# TC37XPD register map
Vendor: Infineon; Series: ATVMC; File version: 100
CPU: other r0p0, little endian, MPU, FPU, vendor SysTick, 4 interrupt priority bits
Registers are 32-bit, read-write, reset 0x0 unless marked. A register's access mark holds for its fields unless they carry their own. Offsets are from the block's base; [hi:lo] are bit positions; lines under a group give offsets from that group; {n}, {i} and the like mark numbered series.

## DOM0 — DOM
Base 0xF8700000
{0x0+0x20*i} SCICTRL[{i}] (i=0..15) group
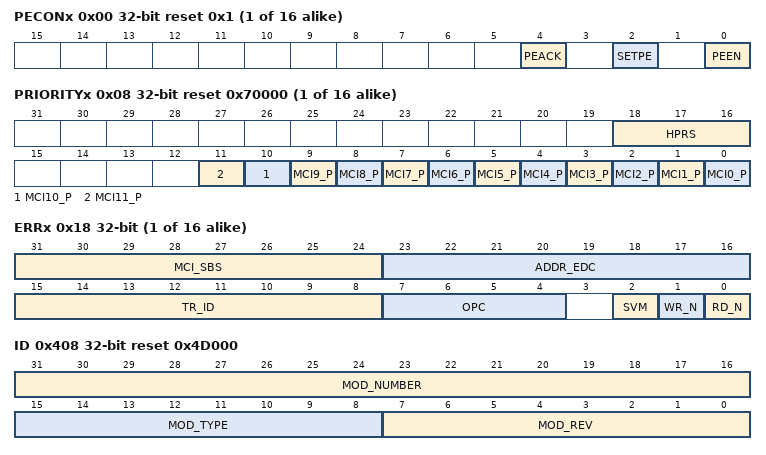
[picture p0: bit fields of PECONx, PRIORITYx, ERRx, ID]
  0x00 PECONx reset 0x1 — Protocol Error Control Register 0 resetvalue={Application Reset:0x1}
    [4] PEACK — Protocol Error Acknowledge PEACK. Writing a one to this bit while it x2019 s set has the following results The error lock of the corresponding ERRADDRx and ERRx are released and the registers will be updated for the next protocol error detected see CROSSREFERENCE . After setting this bit it is automatically cleared by the hardware in the cycle after the write.
    [2] SETPE — Set Protocol Error SETPE. This allows SW to mimic a protocol error and present an indication similar to a hardware detected error. After setting this bit it is automatically cleared by the hardware in the cycle after the write.
    [0] PEEN — Protocol Error Enable PEEN
  0x08 PRIORITYx reset 0x70000 (reset mask 0xFFFFF000) — SCI0 Arbiter Priority Register resetvalue={Application Reset:0x70000}
    [18:16] HPRS — High Priority Round Share HPRS. Number of transactions to give to the high priority round robin before a transaction from low priority round when request saturated . This number may not be less than the number of high priority MCI programmed via. MCIn P.
    [n] MCI{n}_P (n=0..11) — MCI11 Priority MCI11 P
  0x10 ERRADDRx ro — SCI 0 Error Address Capture Register resetvalue={Application Reset:0x0}
    [31:0] ADDR — Transaction Address ADDR. This bitfield contains the address of the erroneous transaction from the address phase
  0x18 ERRx ro — SCI 0 Error Capture Register resetvalue={Application Reset:0x0}
    [31:24] MCI_SBS — MCI Sideband Signals 7 0 MCI SBS. This bit field contains the MCI Sideband Signals 7 0 that are related to the transaction information captured. In the AURIX 8482 TC3xx family the sideband signals are used by the DMA to provide information about the DMA requestor of a DMA transaction for the encoding see CROSSREFERENCE .
    [23:16] ADDR_EDC — Address Phase Error Detection Information ADDR EDC. This field contains the Address Phase Error Detection Information of the erroneous transaction.
    [15:8] TR_ID — Transaction ID TR ID. This field contains the Master 8217 s transaction ID of the erroneous transaction. The Transaction ID is built out of the Master 8217 s 6 bit unique TAG ID TR ID 5 0 and a 2 bit running number TR ID 7 6 .
    [7:4] OPC — Operation Code OPC. This field contains the opcode of the erroneous transaction see CROSSREFERENCE for details.
    [2] SVM — Supervisor Mode Status SVM
    [1] WR_N — Write Status WR
    [0] RD_N — Read Status RD
0x408 ID ro reset 0x4D000 (reset mask 0xFFFFFF00) — Identification Register resetvalue={Application Reset:0x4D000}
  [31:16] MOD_NUMBER — Module Number Value MOD NUMBER. This bit field defines a module identification number. The value for the lt Default Font gt SRI Fabric is 0004H.
  [15:8] MOD_TYPE — Module Type MOD TYPE. The bit field is set to D0H which defines the module as a 32 bit module.
  [7:0] MOD_REV — Module Revision Number MOD REV. This bit field defines the module revision number. The value of a module revision starts with 01H first revision .
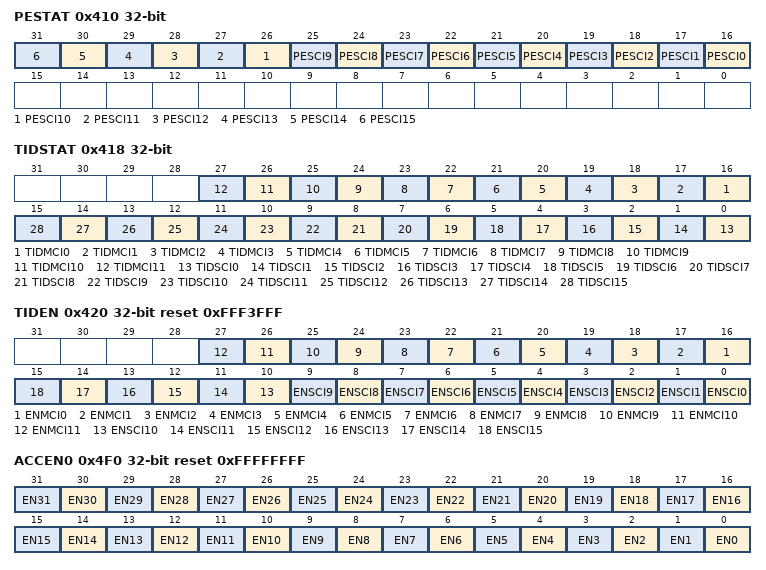
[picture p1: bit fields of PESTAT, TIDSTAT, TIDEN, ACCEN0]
0x410 PESTAT — Protocol Error Status Register resetvalue={Application Reset:0x0}
  [n+16] PESCI{n} (n=0..15) — Protocol Error status of SCI15 PESCI15. Writing 0 to the bit leaves the content unchanged while writing 1 to the bit clears it. In case the bit is simultaneously cleared via software and set via hardware the bit remains set and is not cleared.
0x418 TIDSTAT — Transaction ID Status Register resetvalue={Application Reset:0x0}
  [n+16] TIDMCI{n} (n=0..11) — Tra11saction ID Error from MCIn Status TIDMCI11. Writing 0 to the bit leaves the content unchanged. Writing 1 to the bit clears it. If the bit is simultaneously cleared via software and set due to a hardware error the bit remains set and is not cleared.
  [n] TIDSCI{n} (n=0..15) — Tra15saction ID Error from SCIn Status TIDSCI15. Writing 0 to the bit leaves the content unchanged. Writing 1 to the bit clears it. If the bit is simultaneously cleared via software and set due to a hardware error the bit remains set and is not cleared.
0x420 TIDEN reset 0xFFF3FFF — Transaction ID Enable Register resetvalue={Application Reset:0x0FFF3FFF}
  [n+16] ENMCI{n} (n=0..11) — E11able Transaction ID Error from MCIn ENMCI11
  [n] ENSCI{n} (n=0..15) — E15able Transaction ID Error from SCIn ENSCI15
0x430 BRCON reset not defined — Domain 0 Bridge Control Register resetvalue={Application Reset:0x0,Application Reset:0x200,Application Reset:0x0}
  [0] OLDAEN — Online Data Acquisition Enable OLDAEN. This bit is used to control trap generated for write accesses to the OLDA address range associated with this domain.
0x4F0 ACCEN0 reset 0xFFFFFFFF — Access Enable Register 0 resetvalue={Application Reset:0x0FFFFFFFF}
  [n] EN{n} (n=0..31) — Access Enable for Master TAG ID 31 EN31. This bit enables write access to the module kernel addresses for transactions with the Master TAG ID n
